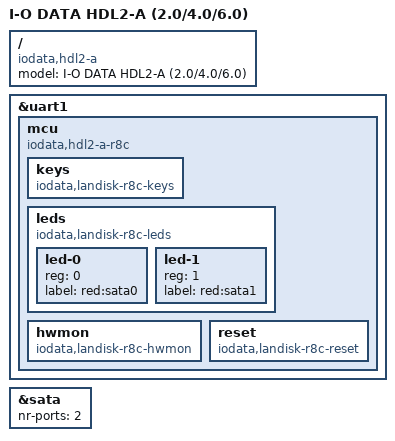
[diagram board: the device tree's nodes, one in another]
// SPDX-License-Identifier: GPL-2.0-or-later OR MIT

#include "kirkwood-hdlx-a.dtsi"

/ {
	model = "I-O DATA HDL2-A (2.0/4.0/6.0)";
	compatible = "iodata,hdl2-a", "marvell,kirkwood-88f6282", "marvell,kirkwood";
};

&uart1 {
	status = "okay";

	mcu {
		compatible = "iodata,hdl2-a-r8c";

		keys {
			compatible = "iodata,landisk-r8c-keys";
		};

		leds {
			compatible = "iodata,landisk-r8c-leds";
			#address-cells = <1>;
			#size-cells = <0>;

			led-0 {
				reg = <0>;
				label = "red:sata0";
			};

			led-1 {
				reg = <1>;
				label = "red:sata1";
			};
		};

		hwmon {
			compatible = "iodata,landisk-r8c-hwmon";
		};

		reset {
			compatible = "iodata,landisk-r8c-reset";
		};
	};
};

&sata {
	status = "okay";
	nr-ports = <2>;
};
